# IVA2_PRM register map
Vendor: Texas Instruments
Peripheral module from a debugger description file (folder omap34xx).
Registers are 32-bit, access per field, reset 0x0 unless marked. A register's access mark holds for its fields unless they carry their own. Offsets are as the file gives them; lines under a group give offsets from that group; [hi:lo] are bit positions; {n}, {i} and the like mark numbered series; 'fields as' and 'values as' point back to an identical list; <NAME> marks a mode.

## IVA2_PRM
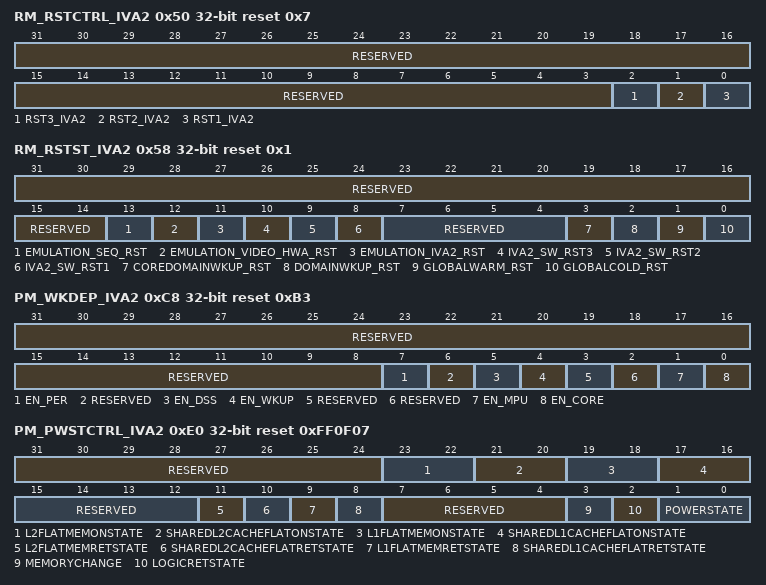
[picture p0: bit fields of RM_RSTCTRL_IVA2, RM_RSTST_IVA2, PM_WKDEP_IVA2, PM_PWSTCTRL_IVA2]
0x50 RM_RSTCTRL_IVA2 reset 0x7 — This register controls the release of the IVA2 sub-system resets.
  [31:3] RESERVED ro — Write 0s for future compatibility. Read returns 0.
  [2] RST3_IVA2 rw — Video sequencer reset control
    0=Video sequencer reset is cleared; 1=Resets video sequencer
  [1] RST2_IVA2 rw — IVA2 - MMU reset control and Video Sequencer hardware accelerator reset control
    0=IVA2 - MMU reset and Video Sequencer hardware accelerator reset are cleared; 1=Resets IVA2 - MMU and Video Sequencer hardware accelerator
  [0] RST1_IVA2 rw — IVA2 - DSP reset control
    0=IVA2 - DSP reset is cleared; 1=Resets IVA2 - DSP
0x58 RM_RSTST_IVA2 reset 0x1 — This register logs the different reset sources of the IVA2 domain. Each bit is set upon release of the domain reset signal. Must be cleared by software.
  [31:14] RESERVED ro — Write 0s for future compatibility. Read returns 0.
  [13] EMULATION_SEQ_RST rw — Emulation reset
    0=EMULATION_SEQ_RST_0_r (No emulation reset.); 0=EMULATION_SEQ_RST_0_w (Status bit unchanged); 1=EMULATION_SEQ_RST_1_r (Video Sequencer has been reset upon an emulation reset); 1=EMULATION_SEQ_RST_1_w (Status bit is cleared to 0.)
  [12] EMULATION_VIDEO_HWA_RST rw — Emulation reset
    0=EMULATION_VIDEO_HWA_RST_0_r (No emulation reset.); 0=EMULATION_VIDEO_HWA_RST_0_w (Status bit unchanged); 1=EMULATION_VIDEO_HWA_RST_1_r (Video Sequencer hardware accelerator has been reset upon an emulation reset); 1=EMULATION_VIDEO_HWA_RST_1_w (Status bit is cleared to 0.)
  [11] EMULATION_IVA2_RST rw — Emulation reset
    0=EMULATION_IVA2_RST_0_r (No emulation reset.); 0=EMULATION_IVA2_RST_0_w (Status bit unchanged); 1=EMULATION_IVA2_RST_1_r (IVA2 (DSP) has been reset upon an emulation reset); 1=EMULATION_IVA2_RST_1_w (Status bit is cleared to 0.)
  [10] IVA2_SW_RST3 rw — IVA2-Video Sequencer software reset
    0=IVA2_SW_RST3_0_r (No IVA2-Video Sequencer software reset occured.); 0=IVA2_SW_RST3_0_w (Status bit unchanged); 1=IVA2_SW_RST3_1_r (IVA2 domain has been reset upon IVA2-Video Sequencer software reset.); 1=IVA2_SW_RST3_1_w (Status bit is cleared to 0.)
  [9] IVA2_SW_RST2 rw — IVA2-MMU software reset
    0=IVA2_SW_RST2_0_r (No IVA2-MMU software reset occured.); 0=IVA2_SW_RST2_0_w (Status bit unchanged); 1=IVA2_SW_RST2_1_r (IVA2 domain has been reset upon IVA2-MMU software reset.); 1=IVA2_SW_RST2_1_w (Status bit is cleared to 0.)
  [8] IVA2_SW_RST1 rw — IVA2 - DSP software reset
    0=IVA2_SW_RST1_0_r (No IVA2-DSP software reset occured.); 0=IVA2_SW_RST1_0_w (Status bit unchanged); 1=IVA2_SW_RST1_1_r (IVA2 domain has been reset upon IVA2-DSP software reset.); 1=IVA2_SW_RST1_1_w (Status bit is cleared to 0.)
  [7:4] RESERVED ro — Write 0s for future compatibility. Read returns 0.
  [3] COREDOMAINWKUP_RST rw — CORE domain wake-up reset
    0=COREDOMAINWKUP_RST_0_r (No power domain wake-up reset.); 0=COREDOMAINWKUP_RST_0_w (Status bit unchanged); 1=COREDOMAINWKUP_RST_1_r (IVA2 domain has been reset following a CORE power domain wake-up from OFF to ON.); 1=COREDOMAINWKUP_RST_1_w (Status bit is cleared to 0.)
  [2] DOMAINWKUP_RST rw — Power domain wake-up reset
    0=DOMAINWKUP_RST_0_r (No DSP domain wake-up.); 0=DOMAINWKUP_RST_0_w (Status bit unchanged); 1=DOMAINWKUP_RST_1_r (IVA2 domain has been reset following an IVA2 domain wake-up.); 1=DOMAINWKUP_RST_1_w (Status bit is cleared to 0.)
  [1] GLOBALWARM_RST rw — Global warm reset
    0=GLOBALWARM_RST_0_r (No Global warm reset.); 0=GLOBALWARM_RST_0_w (Status bit unchanged); 1=GLOBALWARM_RST_1_r (IVA2 domain has been reset upon global warm reset.); 1=GLOBALWARM_RST_1_w (Status bit is cleared to 0.)
  [0] GLOBALCOLD_RST rw — Global cold reset
    0=GLOBALCOLD_RST_0_r (No global cold reset.); 0=GLOBALCOLD_RST_0_w (Status bit unchanged); 1=GLOBALCOLD_RST_1_r (IVA2 domain has been reset upon a global cold reset); 1=GLOBALCOLD_RST_1_w (Status bit is cleared to 0.)
0xC8 PM_WKDEP_IVA2 reset 0xB3 — This register allows enabling or disabling the wake-up of the IVA2 domain upon another domain wakeup events.
  [31:8] RESERVED ro — Write 0s for future compatibility. Read returns 0.
  [7] EN_PER rw — PER domain dependency
    0=IVA2 domain is independent of PER domain wake-up event; 1=IVA2 domain is woken-up upon PER domain wake-up event
  [6] RESERVED ro — Write 0s for future compatibility. Read returns 0.
  [5] EN_DSS rw — WAKEUP domain dependency
    0=IVA2 domain is independent of DSS domain wake-up event; 1=IVA2 domain is woken-up upon DSS domain wake-up event
  [4] EN_WKUP rw — WAKEUP domain dependency
    0=IVA2 domain is independent of WKUP domain wake-up event; 1=IVA2 domain is woken-up upon WKUP domain wake-up event
  [3] RESERVED ro — Write 0s for future compatibility. Read returns 0.
  [2] RESERVED ro — Write 0s for future compatibility. Read returns 0.
  [1] EN_MPU rw — MPU domain dependency
    0=IVA2 domain is independent of MPU domain wake-up event; 1=IVA2 domain is woken-up upon MPU domain wake-up event
  [0] EN_CORE rw — CORE domain dependency
    0=IVA2 domain is independent of CORE domain wake-up event; 1=IVA2 domain is is woken-up upon CORE domain wake-up event
0xE0 PM_PWSTCTRL_IVA2 reset 0xFF0F07 — This register controls the IVA2 domain power state transition.
  [31:24] RESERVED ro — Write 0s for future compatibility. Read returns 0.
  [23:22] L2FLATMEMONSTATE ro — L2 Flat memory state when domain is ON; Other enums: Reserved
    3=L2 Flat memory is always ON when domain is ON
  [21:20] SHAREDL2CACHEFLATONSTATE rw — Shared L2 Cache and Flat memory state when domain is ON
    0=Shared L2 Cache and Flat memory is OFF when domain is ON; 3=Shared L2 Cache and Flat memory is ON when domain is ON
  [19:18] L1FLATMEMONSTATE ro — L1 Flat memory state when domain is ON; Other enums: Reserved
    3=L1 Flat memory is always ON when domain is ON
  [17:16] SHAREDL1CACHEFLATONSTATE ro — Shared L1 Cache and Flat memory state when domain is ON
    3=Shared L1 Cache and Flat memory is always ON when domain is ON
  [15:12] RESERVED ro — Write 0s for future compatibility. Read returns 0.
  [11] L2FLATMEMRETSTATE rw — L2 Flat memory state when domain is RETENTION
    0=L2 Flat memory is OFF when domain is in RETENTION state; 1=L2 Flat memory is retained when domain is in RETENTION state
  [10] SHAREDL2CACHEFLATRETSTATE rw — Shared L2 Cache and Flat memory state when domain is RETENTION
    0=Shared L2 Cache and Flat memory is OFF when domain is in RETENTION state; 1=Shared L2 Cache and Flat memory is retained when domain is in RETENTION state
  [9] L1FLATMEMRETSTATE rw — L1 Flat memory state when domain is RETENTION
    0=L1 Flat memory is OFF when domain is in RETENTION state; 1=L1 Flat memory is retained when domain is in RETENTION state
  [8] SHAREDL1CACHEFLATRETSTATE rw — Shared L1 Cache and Flat memory state when domain is RETENTION
    0=Shared L1 Cache and Flat memory is OFF when domain is in RETENTION state; 1=Shared L1 Cache and Flat memory is retained when domain is in RETENTION state
  [7:4] RESERVED ro — Write 0s for future compatibility. Read returns 0.
  [3] MEMORYCHANGE rw — Memory change control in ON state
    0=Disable memory change; 1=Enable memory change state in ON state. This bit is automaticaly cleared when memory state is effectively changed.
  [2] LOGICRETSTATE rw — Logic state when RETENTION
    0=Logic is OFF when domain is in RETENTION state; 1=Logic is retained when domain is in RETENTION state
  [1:0] POWERSTATE rw — Power state control
    0=OFF state; 1=RETENTION state; 3=ON state
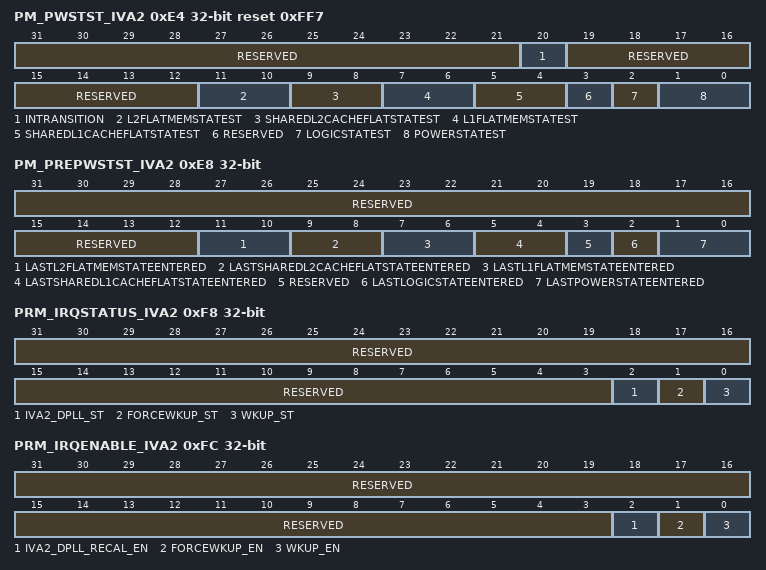
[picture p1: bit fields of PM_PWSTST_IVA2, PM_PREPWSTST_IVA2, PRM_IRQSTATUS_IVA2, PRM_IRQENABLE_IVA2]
0xE4 PM_PWSTST_IVA2 ro reset 0xFF7 — This register provides a status on the power state transition of the IVA2 domain.
  [31:21] RESERVED — Write 0s for future compatibility. Read returns 0.
  [20] INTRANSITION — Domain transition status
    0=No transition; 1=IVA2 power domain transition is in progress
  [19:12] RESERVED — Write 0s for future compatibility. Read returns 0.
  [11:10] L2FLATMEMSTATEST — L2 Flat memory state status
    0=L2 Flat memory is OFF; 1=L2 Flat memory is in RETENTION; 3=L2 Flat memory is ON
  [9:8] SHAREDL2CACHEFLATSTATEST — Shared L2 Cache and Flat memory state status
    0=Shared L2 Cache and Flat memory is OFF; 1=Shared L2 Cache and Flat memory is in RETENTION; 3=Shared L2 Cache and Flat memory is ON
  [7:6] L1FLATMEMSTATEST — L1 Flat memory state status
    0=L1 Flat memory is OFF; 1=L1 Flat memory is in RETENTION; 3=L1 Flat memory is ON
  [5:4] SHAREDL1CACHEFLATSTATEST — Shared L1 Cache and Flat memory state status
    0=Shared L1 Cache and Flat memory is OFF; 1=Shared L1 Cache and Flat memory is in RETENTION; 3=Shared L1 Cache and Flat memory is ON
  [3] RESERVED — Read returns 0.
  [2] LOGICSTATEST — Logic state status
    0=IVA2 domain logic is OFF; 1=IVA2 domain logic is ON
  [1:0] POWERSTATEST — Current power state status
    0=Power domain is OFF; 1=Power domain is in RETENTION; 2=Power domain is INACTIVE; 3=Power domain is ON
0xE8 PM_PREPWSTST_IVA2 — This register provides a status on the IVA2 domain previous power state. It indicates the state entered during the last sleep transition.
  [31:12] RESERVED ro — Read returns 0.
  [11:10] LASTL2FLATMEMSTATEENTERED rw — Last L2 Flat memory state entered
    0=L2 Flat memory was previously OFF; 1=L2 Flat memory was previously in RETENTION; 3=L2 Flat memory was previously ON
  [9:8] LASTSHAREDL2CACHEFLATSTATEENTERED rw — Shared L2 Cache and Flat memory last state entered
    0=Shared L2 Cache and Flat memory was previously OFF; 1=Shared L2 Cache and Flat memory was previously in RETENTION; 3=Shared L2 Cache and Flat memory was previously ON
  [7:6] LASTL1FLATMEMSTATEENTERED rw — Last L1 Flat memory state entered
    0=L1 Flat memory was previously OFF; 1=L1 Flat memory was previously in RETENTION; 3=L1 Flat memory was previously ON
  [5:4] LASTSHAREDL1CACHEFLATSTATEENTERED rw — Shared L1 Cache and Flat memory last state entered
    0=Shared L1 Cache and Flat memory was previously OFF; 1=Shared L1 Cache and Flat memory was previously in RETENTION; 3=Shared L1 Cache and Flat memory was previously ON
  [3] RESERVED ro — Read returns 0.
  [2] LASTLOGICSTATEENTERED rw
    0=IVA2 domain logic was previously OFF; 1=IVA2 domain logic was previously ON
  [1:0] LASTPOWERSTATEENTERED rw
    0=IVA2 domain was previously OFF; 1=IVA2 domain was previously in RETENTION; 2=IVA2 domain was previously INACTIVE; 3=IVA2 domain was previously ON
0xF8 PRM_IRQSTATUS_IVA2 — This interrupt status register regroups all the status of the module internal events that can generate an interrupt. Write 1 to a given bit resets this bit. This register applies on the interrupt line 1 mapped to the IVA2 interrupt controller.
  [31:3] RESERVED ro — Write 0s for future compatibility. Read returns 0.
  [2] IVA2_DPLL_ST rw — DPLL2 recalibration event status
    0=IVA2_DPLL_ST_0_r (DPLL2 recalibration event is false); 0=IVA2_DPLL_ST_0_w (Status bit unchanged); 1=IVA2_DPLL_ST_1_r (DPLL2 recalibration event is true (pending)); 1=IVA2_DPLL_ST_1_w (Status bit is cleared to 0.)
  [1] FORCEWKUP_ST rw — Force wake-up IVA2 domain transition completed event status
    0=FORCEWKUP_ST_0_r (Wake-up event is false); 0=FORCEWKUP_ST_0_w (Status bit unchanged); 1=FORCEWKUP_ST_1_r (Wake-up event is true (pending)); 1=FORCEWKUP_ST_1_w (Status bit is cleared to 0.)
  [0] WKUP_ST rw — IVA2 peripherals group wake-up event status
    0=WKUP_ST_0_r (Wake-up event is false); 0=WKUP_ST_0_w (Status bit unchanged); 1=WKUP_ST_1_r (Wake-up event is true (pending)); 1=WKUP_ST_1_w (Status bit is cleared to 0.)
0xFC PRM_IRQENABLE_IVA2 — The interrupt enable register allows masking/unmasking the module internal sources of interrupt, on a event-by-event basis. This registers applies on the interrupt line 0 mapped to the IVA2 Wake-Up Generator.
  [31:3] RESERVED ro — Write 0s for future compatibility. Read returns 0.
  [2] IVA2_DPLL_RECAL_EN rw — DPLL2 recalibration mask
    0=DPLL2 recalibration event is masked; 1=DPLL2 recalibration event generates an interrupt
  [1] FORCEWKUP_EN rw — Force wake-up IVA2 domain transition completed event mask
    0=Force wake-up IVA2 domain transition completed event is masked; 1=Force wake-up IVA2 domain transition completed event generates an interrupt
  [0] WKUP_EN rw — IVA2 peripherals group wake-up event mask
    0=IVA2 peripherals group wake-up event is masked; 1=IVA2 peripherals group wake-up event generates an interrupt
